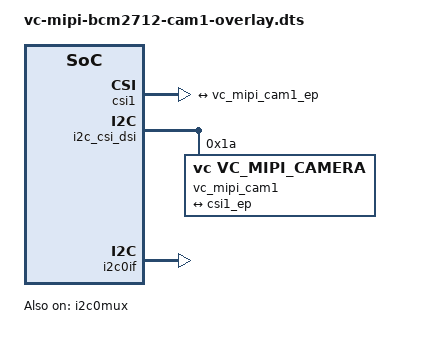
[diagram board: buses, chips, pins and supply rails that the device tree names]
//
// Definitions for cam 1 for RaspberryPi 5
//
// Copyright (C) 2024 - Florian Schmid, Vision Components GmbH
//




/dts-v1/;
/plugin/;

/ {
	fragment@0 {
		target = <&csi1>;
		__overlay__ {
			status = "okay";

			port {
				csi1_ep: endpoint {
					remote-endpoint = <&vc_mipi_cam1_ep>;
					data-lanes = <1 2 3 4>;
				};
			};
		};
	};
	fragment@1 {
		target = <&i2c_csi_dsi>;
		__overlay__ {
			status = "okay";

			#address-cells = <1>;
			#size-cells = <0>;

			vc_mipi_cam1: camera1 {
				compatible = "vc,vc_mipi_camera";
				reg = <0x1a>;
				status = "okay";				
				port {
					vc_mipi_cam1_ep: endpoint {
						remote-endpoint = <&csi1_ep>;
						data-lanes = <1 2 3 4>;

					};
				};
			};
		};
	};
	fragment@2 {
		target = <&i2c0mux>;
		__overlay__ {
			status = "okay";

		};
	};
	fragment@3 {
		target = <&i2c0if>;
		__overlay__ {
			status = "okay";

		};
	};
	fragment@4 {
    	target = <&cam1_reg>;
    	__overlay__ {
       		status = "disabled";
    	};
	};
	fragment@5 {
		target = <&rp1_gpio>;
		__overlay__ {
			cam1_trigger_gpio: cam1_trigger_gpio {
				function = "gpio";
				/* Pin 17 (IO0/CAM_GPIO) of the CAM1 connector, wired to RP1 GPIO46 on
				 * Raspberry Pi 5 Model B. On CM5 this line is shared with cam0_reg's
				 * GPIO34 (no separate CAM1 pin), so cam1 has no independent trigger pin there. */
				pins = "gpio46";
				drive-strength = <0x0c>;   /* optional */
				bias-disable;              /* no pull */
				/* slew-rate = <0x01>; */  /* optional */
			};
		};
	};
	fragment@1001 {
		target = <&i2c_csi_dsi>;
		__dormant__ {
			camera1 {
				port {
						endpoint {
							data-lanes = <1>;
						};
					};
				};
		};
	};
	fragment@1002 {
		target = <&i2c_csi_dsi>;
		__dormant__ {
			camera1 {
				port {
						endpoint {
							data-lanes = <1 2>;

						};
					};
				};
		};
	};
	fragment@1004 {
		target = <&i2c_csi_dsi>;
		__dormant__ {
			camera1 {
				port {
						endpoint {
							data-lanes = <1 2 3 4>;

						};
					};
				};
		};
	};
	fragment@2001 {
		target = <&csi1>;
		__dormant__ {
			status = "okay";
			port {
				endpoint {
					data-lanes = <1>;

				};
			};
		};
	};
	fragment@2002 {
		target = <&csi1>;
		__dormant__ {
			status = "okay";
			port {
				endpoint {
					data-lanes = <1 2>;

				};
			};
		};
	};
	fragment@2004 {
		target = <&csi1>;
		__dormant__ {
			status = "okay";
			port {
				endpoint {
					data-lanes = <1 2 3 4>;

				};
			};
		};
	};



	__overrides__ {
        cam1_lanes1 		=      <0>,"=1001=2001";
		cam1_lanes2 		=      <0>,"=1002=2002";
		cam1_lanes4 		=      <0>,"=1004=2004";		
		cam1_lanes0 	   	= 	   <0>,"-0-1";
		cam1_manu_ov	   	=      <&vc_mipi_cam1>,"reg:0=",<0x60>;
		cam1_manu_os	   	=      <&vc_mipi_cam1>,"reg:0=",<0x36>;
		cam1_libcamera_on 	=      <&vc_mipi_cam1>,"libcamera";
		cam1_force_color	=      <&vc_mipi_cam1>,"force-color-mode";


    };
};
